# RSL15 register map
Vendor: ONSemiconductor; Series: RSL15 Series; File version: 1.0
CPU: CM33 r0p4, little endian, MPU, FPU, 3 interrupt priority bits
Registers are 32-bit, read-write, reset 0x0 unless marked. A register's access mark holds for its fields unless they carry their own. Offsets are from the block's base; [hi:lo] are bit positions; {n}, {i} and the like mark numbered series.

## NVIC — Nested Vector Interrupt Controller
Base 0xE000E100
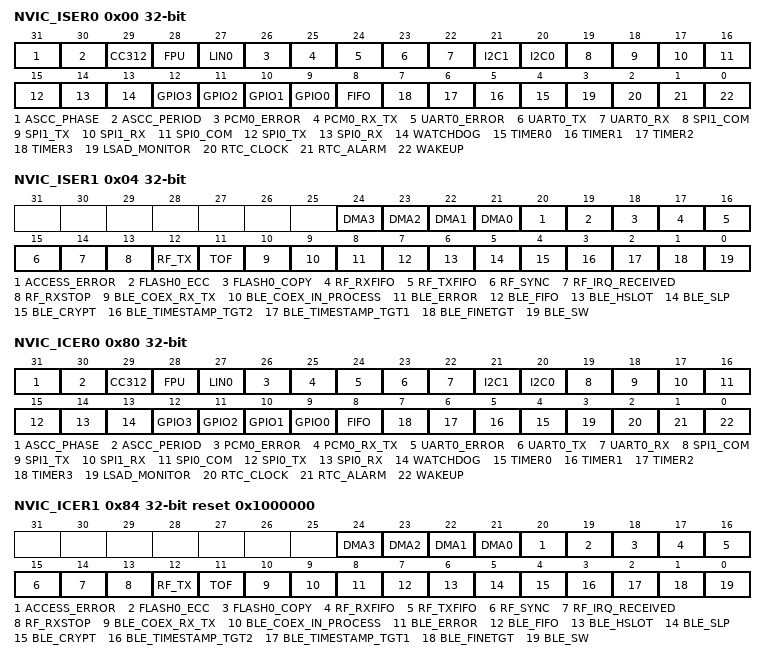
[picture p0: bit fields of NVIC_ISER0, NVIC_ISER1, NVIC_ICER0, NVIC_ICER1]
0x00 NVIC_ISER0 — NVIC External Interrupt Set Enable Register 0
  [31] ASCC_PHASE — ASCC_PHASE interrupt set enable
    1=NVIC_ASCC_PHASE_INT_ENABLE (Enable the ASCC_PHASE interrupt)
  [30] ASCC_PERIOD — ASCC_PERIOD interrupt set enable
    1=NVIC_ASCC_PERIOD_INT_ENABLE (Enable the ASCC_PERIOD interrupt)
  [29] CC312 — CC312 interrupt set enable
    1=NVIC_CC312_INT_ENABLE (Enable the CC312 interrupt)
  [28] FPU — FPU interrupt set enable
    1=NVIC_FPU_INT_ENABLE (Enable the FPU interrupt)
  [27] LIN0 — LIN0 interrupt set enable
    1=NVIC_LIN0_INT_ENABLE (Enable the LIN0 interrupt)
  [26] PCM0_ERROR — PCM0_ERROR interrupt set enable
    1=NVIC_PCM0_ERROR_INT_ENABLE (Enable the PCM0_ERROR interrupt)
  [25] PCM0_RX_TX — PCM0_RX_TX interrupt set enable
    1=NVIC_PCM0_RX_TX_INT_ENABLE (Enable the PCM0_RX_TX interrupt)
  [24] UART0_ERROR — UART0_ERROR interrupt set enable
    1=NVIC_UART0_ERROR_INT_ENABLE (Enable the UART0_ERROR interrupt)
  [23] UART0_TX — UART0_TX interrupt set enable
    1=NVIC_UART0_TX_INT_ENABLE (Enable the UART0_TX interrupt)
  [22] UART0_RX — UART0_RX interrupt set enable
    1=NVIC_UART0_RX_INT_ENABLE (Enable the UART0_RX interrupt)
  [21] I2C1 — I2C1 interrupt set enable
    1=NVIC_I2C1_INT_ENABLE (Enable the I2C1 interrupt)
  [20] I2C0 — I2C0 interrupt set enable
    1=NVIC_I2C0_INT_ENABLE (Enable the I2C0 interrupt)
  [19] SPI1_COM — SPI1_COM interrupt set enable
    1=NVIC_SPI1_COM_INT_ENABLE (Enable the SPI1_COM interrupt)
  [18] SPI1_TX — SPI1_TX interrupt set enable
    1=NVIC_SPI1_TX_INT_ENABLE (Enable the SPI1_TX interrupt)
  [17] SPI1_RX — SPI1_RX interrupt set enable
    1=NVIC_SPI1_RX_INT_ENABLE (Enable the SPI1_RX interrupt)
  [16] SPI0_COM — SPI0_COM interrupt set enable
    1=NVIC_SPI0_COM_INT_ENABLE (Enable the SPI0_COM interrupt)
  [15] SPI0_TX — SPI0_TX interrupt set enable
    1=NVIC_SPI0_TX_INT_ENABLE (Enable the SPI0_TX interrupt)
  [14] SPI0_RX — SPI0_RX interrupt set enable
    1=NVIC_SPI0_RX_INT_ENABLE (Enable the SPI0_RX interrupt)
  [13] WATCHDOG — WATCHDOG interrupt set enable
    1=NVIC_WATCHDOG_INT_ENABLE (Enable the WATCHDOG interrupt)
  [n+9] GPIO{n} (n=0..3) — GPIO{n} interrupt set enable
    1=NVIC_GPIO{n}_INT_ENABLE (Enable the GPIO{n} interrupt)
  [8] FIFO — FIFO interrupt set enable
    1=NVIC_FIFO_INT_ENABLE (Enable the FIFO interrupt)
  [n+4] TIMER{n} (n=0..3) — TIMER{n} interrupt set enable
    1=NVIC_TIMER{n}_INT_ENABLE (Enable the TIMER{n} interrupt)
  [3] LSAD_MONITOR — LSAD_MONITOR interrupt set enable
    1=NVIC_LSAD_MONITOR_INT_ENABLE (Enable the LSAD_MONITOR interrupt)
  [2] RTC_CLOCK — RTC_CLOCK interrupt set enable
    1=NVIC_RTC_CLOCK_INT_ENABLE (Enable the RTC_CLOCK interrupt)
  [1] RTC_ALARM — RTC_ALARM interrupt set enable
    1=NVIC_RTC_ALARM_INT_ENABLE (Enable the RTC_ALARM interrupt)
  [0] WAKEUP — WAKEUP interrupt set enable
    1=NVIC_WAKEUP_INT_ENABLE (Enable the WAKEUP interrupt)
0x04 NVIC_ISER1 — NVIC External Interrupt Set Enable Register 1
  [n+21] DMA{n} (n=0..3) — DMA{n} interrupt set enable
    1=NVIC_DMA{n}_INT_ENABLE (Enable the DMA{n} interrupt)
  [20] ACCESS_ERROR — ACCESS_ERROR interrupt set enable
    1=NVIC_ACCESS_ERROR_INT_ENABLE (Enable the ACCESS_ERROR interrupt)
  [19] FLASH0_ECC — FLASH0_ECC interrupt set enable
    1=NVIC_FLASH0_ECC_INT_ENABLE (Enable the FLASH0_ECC interrupt)
  [18] FLASH0_COPY — FLASH0_COPY interrupt set enable
    1=NVIC_FLASH0_COPY_INT_ENABLE (Enable the FLASH0_COPY interrupt)
  [17] RF_RXFIFO — RF_RXFIFO interrupt set enable
    1=NVIC_RF_RXFIFO_INT_ENABLE (Enable the RF_RXFIFO interrupt)
  [16] RF_TXFIFO — RF_TXFIFO interrupt set enable
    1=NVIC_RF_TXFIFO_INT_ENABLE (Enable the RF_TXFIFO interrupt)
  [15] RF_SYNC — RF_SYNC interrupt set enable
    1=NVIC_RF_SYNC_INT_ENABLE (Enable the RF_SYNC interrupt)
  [14] RF_IRQ_RECEIVED — RF_IRQ_RECEIVED interrupt set enable
    1=NVIC_RF_IRQ_RECEIVED_INT_ENABLE (Enable the RF_IRQ_RECEIVED interrupt)
  [13] RF_RXSTOP — RF_RXSTOP interrupt set enable
    1=NVIC_RF_RXSTOP_INT_ENABLE (Enable the RF_RXSTOP interrupt)
  [12] RF_TX — RF_TX interrupt set enable
    1=NVIC_RF_TX_INT_ENABLE (Enable the RF_TX interrupt)
  [11] TOF — TOF interrupt set enable
    1=NVIC_TOF_INT_ENABLE (Enable the TOF interrupt)
  [10] BLE_COEX_RX_TX — BLE_COEX_RX_TX interrupt set enable
    1=NVIC_BLE_COEX_RX_TX_INT_ENABLE (Enable the BLE_COEX_RX_TX interrupt)
  [9] BLE_COEX_IN_PROCESS — BLE_COEX_IN_PROCESS interrupt set enable
    1=NVIC_BLE_COEX_IN_PROCESS_INT_ENABLE (Enable the BLE_COEX_IN_PROCESS interrupt)
  [8] BLE_ERROR — BLE_ERROR interrupt set enable
    1=NVIC_BLE_ERROR_INT_ENABLE (Enable the BLE_ERROR interrupt)
  [7] BLE_FIFO — BLE_FIFO interrupt set enable
    1=NVIC_BLE_FIFO_INT_ENABLE (Enable the BLE_FIFO interrupt)
  [6] BLE_HSLOT — BLE_HSLOT interrupt set enable
    1=NVIC_BLE_HSLOT_INT_ENABLE (Enable the BLE_HSLOT interrupt)
  [5] BLE_SLP — BLE_SLP interrupt set enable
    1=NVIC_BLE_SLP_INT_ENABLE (Enable the BLE_SLP interrupt)
  [4] BLE_CRYPT — BLE_CRYPT interrupt set enable
    1=NVIC_BLE_CRYPT_INT_ENABLE (Enable the BLE_CRYPT interrupt)
  [3] BLE_TIMESTAMP_TGT2 — BLE_TIMESTAMP_TGT2 interrupt set enable
    1=NVIC_BLE_TIMESTAMP_TGT2_INT_ENABLE (Enable the BLE_TIMESTAMP_TGT2 interrupt)
  [2] BLE_TIMESTAMP_TGT1 — BLE_TIMESTAMP_TGT1 interrupt set enable
    1=NVIC_BLE_TIMESTAMP_TGT1_INT_ENABLE (Enable the BLE_TIMESTAMP_TGT1 interrupt)
  [1] BLE_FINETGT — BLE_FINETGT interrupt set enable
    1=NVIC_BLE_FINETGT_INT_ENABLE (Enable the BLE_FINETGT interrupt)
  [0] BLE_SW — BLE_SW interrupt set enable
    1=NVIC_BLE_SW_INT_ENABLE (Enable the BLE_SW interrupt)
0x80 NVIC_ICER0 — NVIC External Interrupt Clear Enable Register 0
  [31] ASCC_PHASE — ASCC_PHASE interrupt clear enable
    1=NVIC_ASCC_PHASE_INT_DISABLE (Disable the ASCC_PHASE interrupt)
  [30] ASCC_PERIOD — ASCC_PERIOD interrupt clear enable
    1=NVIC_ASCC_PERIOD_INT_DISABLE (Disable the ASCC_PERIOD interrupt)
  [29] CC312 — CC312 interrupt clear enable
    1=NVIC_CC312_INT_DISABLE (Disable the CC312 interrupt)
  [28] FPU — FPU interrupt clear enable
    1=NVIC_FPU_INT_DISABLE (Disable the FPU interrupt)
  [27] LIN0 — LIN0 interrupt clear enable
    1=NVIC_LIN0_INT_DISABLE (Disable the LIN0 interrupt)
  [26] PCM0_ERROR — PCM0_ERROR interrupt clear enable
    1=NVIC_PCM0_ERROR_INT_DISABLE (Disable the PCM0_ERROR interrupt)
  [25] PCM0_RX_TX — PCM0_RX_TX interrupt clear enable
    1=NVIC_PCM0_RX_TX_INT_DISABLE (Disable the PCM0_RX_TX interrupt)
  [24] UART0_ERROR — UART0_ERROR interrupt clear enable
    1=NVIC_UART0_ERROR_INT_DISABLE (Disable the UART0_ERROR interrupt)
  [23] UART0_TX — UART0_TX interrupt clear enable
    1=NVIC_UART0_TX_INT_DISABLE (Disable the UART0_TX interrupt)
  [22] UART0_RX — UART0_RX interrupt clear enable
    1=NVIC_UART0_RX_INT_DISABLE (Disable the UART0_RX interrupt)
  [21] I2C1 — I2C1 interrupt clear enable
    1=NVIC_I2C1_INT_DISABLE (Disable the I2C1 interrupt)
  [20] I2C0 — I2C0 interrupt clear enable
    1=NVIC_I2C0_INT_DISABLE (Disable the I2C0 interrupt)
  [19] SPI1_COM — SPI1_COM interrupt clear enable
    1=NVIC_SPI1_COM_INT_DISABLE (Disable the SPI1_COM interrupt)
  [18] SPI1_TX — SPI1_TX interrupt clear enable
    1=NVIC_SPI1_TX_INT_DISABLE (Disable the SPI1_TX interrupt)
  [17] SPI1_RX — SPI1_RX interrupt clear enable
    1=NVIC_SPI1_RX_INT_DISABLE (Disable the SPI1_RX interrupt)
  [16] SPI0_COM — SPI0_COM interrupt clear enable
    1=NVIC_SPI0_COM_INT_DISABLE (Disable the SPI0_COM interrupt)
  [15] SPI0_TX — SPI0_TX interrupt clear enable
    1=NVIC_SPI0_TX_INT_DISABLE (Disable the SPI0_TX interrupt)
  [14] SPI0_RX — SPI0_RX interrupt clear enable
    1=NVIC_SPI0_RX_INT_DISABLE (Disable the SPI0_RX interrupt)
  [13] WATCHDOG — WATCHDOG interrupt clear enable
    1=NVIC_WATCHDOG_INT_DISABLE (Disable the WATCHDOG interrupt)
  [n+9] GPIO{n} (n=0..3) — GPIO{n} interrupt clear enable
    1=NVIC_GPIO{n}_INT_DISABLE (Disable the GPIO{n} interrupt)
  [8] FIFO — FIFO interrupt clear enable
    1=NVIC_FIFO_INT_DISABLE (Disable the FIFO interrupt)
  [n+4] TIMER{n} (n=0..3) — TIMER{n} interrupt clear enable
    1=NVIC_TIMER{n}_INT_DISABLE (Disable the TIMER{n} interrupt)
  [3] LSAD_MONITOR — LSAD_MONITOR interrupt clear enable
    1=NVIC_LSAD_MONITOR_INT_DISABLE (Disable the LSAD_MONITOR interrupt)
  [2] RTC_CLOCK — RTC_CLOCK interrupt clear enable
    1=NVIC_RTC_CLOCK_INT_DISABLE (Disable the RTC_CLOCK interrupt)
  [1] RTC_ALARM — RTC_ALARM interrupt clear enable
    1=NVIC_RTC_ALARM_INT_DISABLE (Disable the RTC_ALARM interrupt)
  [0] WAKEUP — WAKEUP interrupt clear enable
    1=NVIC_WAKEUP_INT_DISABLE (Disable the WAKEUP interrupt)
0x84 NVIC_ICER1 reset 0x1000000 — NVIC External Interrupt Clear Enable Register 1
  [24] DMA3 — DMA3 interrupt clear enable
    0=NVIC_DMA3_INT_DISABLE (Disable the DMA3 interrupt)
  [23] DMA2 — DMA2 interrupt clear enable
    1=NVIC_DMA2_INT_DISABLE (Disable the DMA2 interrupt)
  [22] DMA1 — DMA1 interrupt clear enable
    1=NVIC_DMA1_INT_DISABLE (Disable the DMA1 interrupt)
  [21] DMA0 — DMA0 interrupt clear enable
    1=NVIC_DMA0_INT_DISABLE (Disable the DMA0 interrupt)
  [20] ACCESS_ERROR — ACCESS_ERROR interrupt clear enable
    1=NVIC_ACCESS_ERROR_INT_DISABLE (Disable the ACCESS_ERROR interrupt)
  [19] FLASH0_ECC — FLASH0_ECC interrupt clear enable
    1=NVIC_FLASH0_ECC_INT_DISABLE (Disable the FLASH0_ECC interrupt)
  [18] FLASH0_COPY — FLASH0_COPY interrupt clear enable
    1=NVIC_FLASH0_COPY_INT_DISABLE (Disable the FLASH0_COPY interrupt)
  [17] RF_RXFIFO — RF_RXFIFO interrupt clear enable
    1=NVIC_RF_RXFIFO_INT_DISABLE (Disable the RF_RXFIFO interrupt)
  [16] RF_TXFIFO — RF_TXFIFO interrupt clear enable
    1=NVIC_RF_TXFIFO_INT_DISABLE (Disable the RF_TXFIFO interrupt)
  [15] RF_SYNC — RF_SYNC interrupt clear enable
    1=NVIC_RF_SYNC_INT_DISABLE (Disable the RF_SYNC interrupt)
  [14] RF_IRQ_RECEIVED — RF_IRQ_RECEIVED interrupt clear enable
    1=NVIC_RF_IRQ_RECEIVED_INT_DISABLE (Disable the RF_IRQ_RECEIVED interrupt)
  [13] RF_RXSTOP — RF_RXSTOP interrupt clear enable
    1=NVIC_RF_RXSTOP_INT_DISABLE (Disable the RF_RXSTOP interrupt)
  [12] RF_TX — RF_TX interrupt clear enable
    1=NVIC_RF_TX_INT_DISABLE (Disable the RF_TX interrupt)
  [11] TOF — TOF interrupt clear enable
    1=NVIC_TOF_INT_DISABLE (Disable the TOF interrupt)
  [10] BLE_COEX_RX_TX — BLE_COEX_RX_TX interrupt clear enable
    1=NVIC_BLE_COEX_RX_TX_INT_DISABLE (Disable the BLE_COEX_RX_TX interrupt)
  [9] BLE_COEX_IN_PROCESS — BLE_COEX_IN_PROCESS interrupt clear enable
    1=NVIC_BLE_COEX_IN_PROCESS_INT_DISABLE (Disable the BLE_COEX_IN_PROCESS interrupt)
  [8] BLE_ERROR — BLE_ERROR interrupt clear enable
    1=NVIC_BLE_ERROR_INT_DISABLE (Disable the BLE_ERROR interrupt)
  [7] BLE_FIFO — BLE_FIFO interrupt clear enable
    1=NVIC_BLE_FIFO_INT_DISABLE (Disable the BLE_FIFO interrupt)
  [6] BLE_HSLOT — BLE_HSLOT interrupt clear enable
    1=NVIC_BLE_HSLOT_INT_DISABLE (Disable the BLE_HSLOT interrupt)
  [5] BLE_SLP — BLE_SLP interrupt clear enable
    1=NVIC_BLE_SLP_INT_DISABLE (Disable the BLE_SLP interrupt)
  [4] BLE_CRYPT — BLE_CRYPT interrupt clear enable
    1=NVIC_BLE_CRYPT_INT_DISABLE (Disable the BLE_CRYPT interrupt)
  [3] BLE_TIMESTAMP_TGT2 — BLE_TIMESTAMP_TGT2 interrupt clear enable
    1=NVIC_BLE_TIMESTAMP_TGT2_INT_DISABLE (Disable the BLE_TIMESTAMP_TGT2 interrupt)
  [2] BLE_TIMESTAMP_TGT1 — BLE_TIMESTAMP_TGT1 interrupt clear enable
    1=NVIC_BLE_TIMESTAMP_TGT1_INT_DISABLE (Disable the BLE_TIMESTAMP_TGT1 interrupt)
  [1] BLE_FINETGT — BLE_FINETGT interrupt clear enable
    1=NVIC_BLE_FINETGT_INT_DISABLE (Disable the BLE_FINETGT interrupt)
  [0] BLE_SW — BLE_SW interrupt clear enable
    1=NVIC_BLE_SW_INT_DISABLE (Disable the BLE_SW interrupt)
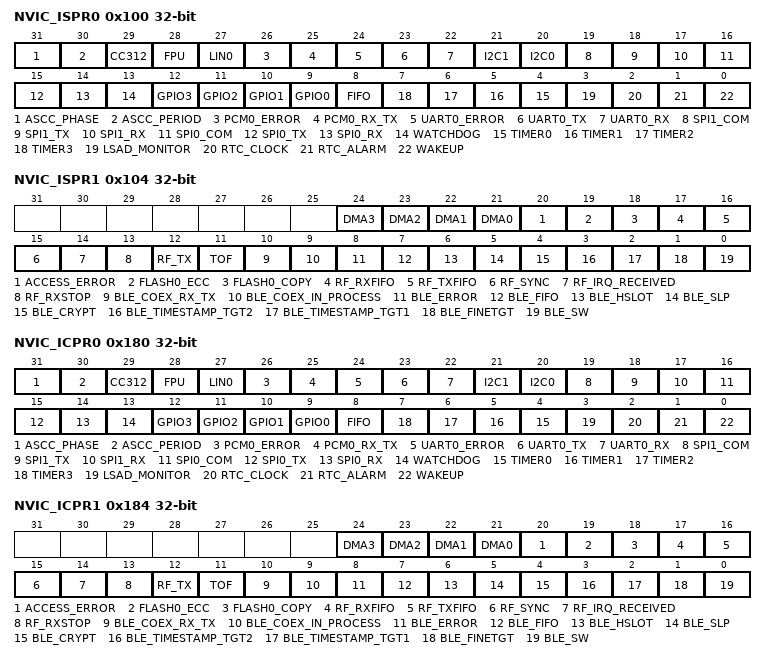
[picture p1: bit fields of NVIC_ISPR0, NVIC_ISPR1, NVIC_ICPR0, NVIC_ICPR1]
0x100 NVIC_ISPR0 — NVIC External Interrupt Set Pending Register 0
  [31] ASCC_PHASE — ASCC_PHASE interrupt set pending
    1=NVIC_ASCC_PHASE_INT_SETPEND (Set the ASCC_PHASE interrupt pending)
  [30] ASCC_PERIOD — ASCC_PERIOD interrupt set pending
    1=NVIC_ASCC_PERIOD_INT_SETPEND (Set the ASCC_PERIOD interrupt pending)
  [29] CC312 — CC312 interrupt set pending
    1=NVIC_CC312_INT_SETPEND (Set the CC312 interrupt pending)
  [28] FPU — FPU interrupt set pending
    1=NVIC_FPU_INT_SETPEND (Set the FPU interrupt pending)
  [27] LIN0 — LIN0 interrupt set pending
    1=NVIC_LIN0_INT_SETPEND (Set the LIN0 interrupt pending)
  [26] PCM0_ERROR — PCM0_ERROR interrupt set pending
    1=NVIC_PCM0_ERROR_INT_SETPEND (Set the PCM0_ERROR interrupt pending)
  [25] PCM0_RX_TX — PCM0_RX_TX interrupt set pending
    1=NVIC_PCM0_RX_TX_INT_SETPEND (Set the PCM0_RX_TX interrupt pending)
  [24] UART0_ERROR — UART0_ERROR interrupt set pending
    1=NVIC_UART0_ERROR_INT_SETPEND (Set the UART0_ERROR interrupt pending)
  [23] UART0_TX — UART0_TX interrupt set pending
    1=NVIC_UART0_TX_INT_SETPEND (Set the UART0_TX interrupt pending)
  [22] UART0_RX — UART0_RX interrupt set pending
    1=NVIC_UART0_RX_INT_SETPEND (Set the UART0_RX interrupt pending)
  [21] I2C1 — I2C1 interrupt set pending
    1=NVIC_I2C1_INT_SETPEND (Set the I2C1 interrupt pending)
  [20] I2C0 — I2C0 interrupt set pending
    1=NVIC_I2C0_INT_SETPEND (Set the I2C0 interrupt pending)
  [19] SPI1_COM — SPI1_COM interrupt set pending
    1=NVIC_SPI1_COM_INT_SETPEND (Set the SPI1_COM interrupt pending)
  [18] SPI1_TX — SPI1_TX interrupt set pending
    1=NVIC_SPI1_TX_INT_SETPEND (Set the SPI1_TX interrupt pending)
  [17] SPI1_RX — SPI1_RX interrupt set pending
    1=NVIC_SPI1_RX_INT_SETPEND (Set the SPI1_RX interrupt pending)
  [16] SPI0_COM — SPI0_COM interrupt set pending
    1=NVIC_SPI0_COM_INT_SETPEND (Set the SPI0_COM interrupt pending)
  [15] SPI0_TX — SPI0_TX interrupt set pending
    1=NVIC_SPI0_TX_INT_SETPEND (Set the SPI0_TX interrupt pending)
  [14] SPI0_RX — SPI0_RX interrupt set pending
    1=NVIC_SPI0_RX_INT_SETPEND (Set the SPI0_RX interrupt pending)
  [13] WATCHDOG — WATCHDOG interrupt set pending
    1=NVIC_WATCHDOG_INT_SETPEND (Set the WATCHDOG interrupt pending)
  [n+9] GPIO{n} (n=0..3) — GPIO{n} interrupt set pending
    1=NVIC_GPIO{n}_INT_SETPEND (Set the GPIO{n} interrupt pending)
  [8] FIFO — FIFO interrupt set pending
    1=NVIC_FIFO_INT_SETPEND (Set the FIFO interrupt pending)
  [n+4] TIMER{n} (n=0..3) — TIMER{n} interrupt set pending
    1=NVIC_TIMER{n}_INT_SETPEND (Set the TIMER{n} interrupt pending)
  [3] LSAD_MONITOR — LSAD_MONITOR interrupt set pending
    1=NVIC_LSAD_MONITOR_INT_SETPEND (Set the LSAD_MONITOR interrupt pending)
  [2] RTC_CLOCK — RTC_CLOCK interrupt set pending
    1=NVIC_RTC_CLOCK_INT_SETPEND (Set the RTC_CLOCK interrupt pending)
  [1] RTC_ALARM — RTC_ALARM interrupt set pending
    1=NVIC_RTC_ALARM_INT_SETPEND (Set the RTC_ALARM interrupt pending)
  [0] WAKEUP — WAKEUP interrupt set pending
    1=NVIC_WAKEUP_INT_SETPEND (Set the WAKEUP interrupt pending)
0x104 NVIC_ISPR1 — NVIC External Interrupt Set Pending Register 1
  [n+21] DMA{n} (n=0..3) — DMA{n} interrupt set pending
    1=NVIC_DMA{n}_INT_SETPEND (Set the DMA{n} interrupt pending)
  [20] ACCESS_ERROR — ACCESS_ERROR interrupt set pending
    1=NVIC_ACCESS_ERROR_INT_SETPEND (Set the ACCESS_ERROR interrupt pending)
  [19] FLASH0_ECC — FLASH0_ECC interrupt set pending
    1=NVIC_FLASH0_ECC_INT_SETPEND (Set the FLASH0_ECC interrupt pending)
  [18] FLASH0_COPY — FLASH0_COPY interrupt set pending
    1=NVIC_FLASH0_COPY_INT_SETPEND (Set the FLASH0_COPY interrupt pending)
  [17] RF_RXFIFO — RF_RXFIFO interrupt set pending
    1=NVIC_RF_RXFIFO_INT_SETPEND (Set the RF_RXFIFO interrupt pending)
  [16] RF_TXFIFO — RF_TXFIFO interrupt set pending
    1=NVIC_RF_TXFIFO_INT_SETPEND (Set the RF_TXFIFO interrupt pending)
  [15] RF_SYNC — RF_SYNC interrupt set pending
    1=NVIC_RF_SYNC_INT_SETPEND (Set the RF_SYNC interrupt pending)
  [14] RF_IRQ_RECEIVED — RF_IRQ_RECEIVED interrupt set pending
    1=NVIC_RF_IRQ_RECEIVED_INT_SETPEND (Set the RF_IRQ_RECEIVED interrupt pending)
  [13] RF_RXSTOP — RF_RXSTOP interrupt set pending
    1=NVIC_RF_RXSTOP_INT_SETPEND (Set the RF_RXSTOP interrupt pending)
  [12] RF_TX — RF_TX interrupt set pending
    1=NVIC_RF_TX_INT_SETPEND (Set the RF_TX interrupt pending)
  [11] TOF — TOF interrupt set pending
    1=NVIC_TOF_INT_SETPEND (Set the TOF interrupt pending)
  [10] BLE_COEX_RX_TX — BLE_COEX_RX_TX interrupt set pending
    1=NVIC_BLE_COEX_RX_TX_INT_SETPEND (Set the BLE_COEX_RX_TX interrupt pending)
  [9] BLE_COEX_IN_PROCESS — BLE_COEX_IN_PROCESS interrupt set pending
    1=NVIC_BLE_COEX_IN_PROCESS_INT_SETPEND (Set the BLE_COEX_IN_PROCESS interrupt pending)
  [8] BLE_ERROR — BLE_ERROR interrupt set pending
    1=NVIC_BLE_ERROR_INT_SETPEND (Set the BLE_ERROR interrupt pending)
  [7] BLE_FIFO — BLE_FIFO interrupt set pending
    1=NVIC_BLE_FIFO_INT_SETPEND (Set the BLE_FIFO interrupt pending)
  [6] BLE_HSLOT — BLE_HSLOT interrupt set pending
    1=NVIC_BLE_HSLOT_INT_SETPEND (Set the BLE_HSLOT interrupt pending)
  [5] BLE_SLP — BLE_SLP interrupt set pending
    1=NVIC_BLE_SLP_INT_SETPEND (Set the BLE_SLP interrupt pending)
  [4] BLE_CRYPT — BLE_CRYPT interrupt set pending
    1=NVIC_BLE_CRYPT_INT_SETPEND (Set the BLE_CRYPT interrupt pending)
  [3] BLE_TIMESTAMP_TGT2 — BLE_TIMESTAMP_TGT2 interrupt set pending
    1=NVIC_BLE_TIMESTAMP_TGT2_INT_SETPEND (Set the BLE_TIMESTAMP_TGT2 interrupt pending)
  [2] BLE_TIMESTAMP_TGT1 — BLE_TIMESTAMP_TGT1 interrupt set pending
    1=NVIC_BLE_TIMESTAMP_TGT1_INT_SETPEND (Set the BLE_TIMESTAMP_TGT1 interrupt pending)
  [1] BLE_FINETGT — BLE_FINETGT interrupt set pending
    1=NVIC_BLE_FINETGT_INT_SETPEND (Set the BLE_FINETGT interrupt pending)
  [0] BLE_SW — BLE_SW interrupt set pending
    1=NVIC_BLE_SW_INT_SETPEND (Set the BLE_SW interrupt pending)
0x180 NVIC_ICPR0 — NVIC External Interrupt Clear Pending Register 0
  [31] ASCC_PHASE — ASCC_PHASE interrupt clear pending
    1=NVIC_ASCC_PHASE_INT_CLRPEND (Clear the NVIC_ASCC_PHASE_INT_CLRPEND interrupt status bit)
  [30] ASCC_PERIOD — ASCC_PERIOD interrupt clear pending
    1=NVIC_ASCC_PERIOD_INT_CLRPEND (Clear the NVIC_ASCC_PERIOD_INT_CLRPEND interrupt status bit)
  [29] CC312 — CC312 interrupt clear pending
    1=NVIC_CC312_INT_CLRPEND (Clear the NVIC_CC312_INT_CLRPEND interrupt status bit)
  [28] FPU — FPU interrupt clear pending
    1=NVIC_FPU_INT_CLRPEND (Clear the NVIC_FPU_INT_CLRPEND interrupt status bit)
  [27] LIN0 — LIN0 interrupt clear pending
    1=NVIC_LIN0_INT_CLRPEND (Clear the NVIC_LIN0_INT_CLRPEND interrupt status bit)
  [26] PCM0_ERROR — PCM0_ERROR interrupt clear pending
    1=NVIC_PCM0_ERROR_INT_CLRPEND (Clear the NVIC_PCM0_ERROR_INT_CLRPEND interrupt status bit)
  [25] PCM0_RX_TX — PCM0_RX_TX interrupt clear pending
    1=NVIC_PCM0_RX_TX_INT_CLRPEND (Clear the NVIC_PCM0_RX_TX_INT_CLRPEND interrupt status bit)
  [24] UART0_ERROR — UART0_ERROR interrupt clear pending
    1=NVIC_UART0_ERROR_INT_CLRPEND (Clear the NVIC_UART0_ERROR_INT_CLRPEND interrupt status bit)
  [23] UART0_TX — UART0_TX interrupt clear pending
    1=NVIC_UART0_TX_INT_CLRPEND (Clear the NVIC_UART0_TX_INT_CLRPEND interrupt status bit)
  [22] UART0_RX — UART0_RX interrupt clear pending
    1=NVIC_UART0_RX_INT_CLRPEND (Clear the NVIC_UART0_RX_INT_CLRPEND interrupt status bit)
  [21] I2C1 — I2C1 interrupt clear pending
    1=NVIC_I2C1_INT_CLRPEND (Clear the NVIC_I2C1_INT_CLRPEND interrupt status bit)
  [20] I2C0 — I2C0 interrupt clear pending
    1=NVIC_I2C0_INT_CLRPEND (Clear the NVIC_I2C0_INT_CLRPEND interrupt status bit)
  [19] SPI1_COM — SPI1_COM interrupt clear pending
    1=NVIC_SPI1_COM_INT_CLRPEND (Clear the NVIC_SPI1_COM_INT_CLRPEND interrupt status bit)
  [18] SPI1_TX — SPI1_TX interrupt clear pending
    1=NVIC_SPI1_TX_INT_CLRPEND (Clear the NVIC_SPI1_TX_INT_CLRPEND interrupt status bit)
  [17] SPI1_RX — SPI1_RX interrupt clear pending
    1=NVIC_SPI1_RX_INT_CLRPEND (Clear the NVIC_SPI1_RX_INT_CLRPEND interrupt status bit)
  [16] SPI0_COM — SPI0_COM interrupt clear pending
    1=NVIC_SPI0_COM_INT_CLRPEND (Clear the NVIC_SPI0_COM_INT_CLRPEND interrupt status bit)
  [15] SPI0_TX — SPI0_TX interrupt clear pending
    1=NVIC_SPI0_TX_INT_CLRPEND (Clear the NVIC_SPI0_TX_INT_CLRPEND interrupt status bit)
  [14] SPI0_RX — SPI0_RX interrupt clear pending
    1=NVIC_SPI0_RX_INT_CLRPEND (Clear the NVIC_SPI0_RX_INT_CLRPEND interrupt status bit)
  [13] WATCHDOG — WATCHDOG interrupt clear pending
    1=NVIC_WATCHDOG_INT_CLRPEND (Clear the NVIC_WATCHDOG_INT_CLRPEND interrupt status bit)
  [n+9] GPIO{n} (n=0..3) — GPIO{n} interrupt clear pending
    1=NVIC_GPIO{n}_INT_CLRPEND (Clear the NVIC_GPIO{n}_INT_CLRPEND interrupt status bit)
  [8] FIFO — FIFO interrupt clear pending
    1=NVIC_FIFO_INT_CLRPEND (Clear the NVIC_FIFO_INT_CLRPEND interrupt status bit)
  [n+4] TIMER{n} (n=0..3) — TIMER{n} interrupt clear pending
    1=NVIC_TIMER{n}_INT_CLRPEND (Clear the NVIC_TIMER{n}_INT_CLRPEND interrupt status bit)
  [3] LSAD_MONITOR — LSAD_MONITOR interrupt clear pending
    1=NVIC_LSAD_MONITOR_INT_CLRPEND (Clear the NVIC_LSAD_MONITOR_INT_CLRPEND interrupt status bit)
  [2] RTC_CLOCK — RTC_CLOCK interrupt clear pending
    1=NVIC_RTC_CLOCK_INT_CLRPEND (Clear the NVIC_RTC_CLOCK_INT_CLRPEND interrupt status bit)
  [1] RTC_ALARM — RTC_ALARM interrupt clear pending
    1=NVIC_RTC_ALARM_INT_CLRPEND (Clear the NVIC_RTC_ALARM_INT_CLRPEND interrupt status bit)
  [0] WAKEUP — WAKEUP interrupt clear pending
    1=NVIC_WAKEUP_INT_CLRPEND (Clear the NVIC_WAKEUP_INT_CLRPEND interrupt status bit)
0x184 NVIC_ICPR1 — NVIC External Interrupt Clear Pending Register 1
  [n+21] DMA{n} (n=0..3) — DMA{n} interrupt clear pending
    1=NVIC_DMA{n}_INT_CLRPEND (Clear the NVIC_DMA{n}_INT_CLRPEND interrupt status bit)
  [20] ACCESS_ERROR — ACCESS_ERROR interrupt clear pending
    1=NVIC_ACCESS_ERROR_INT_CLRPEND (Clear the NVIC_ACCESS_ERROR_INT_CLRPEND interrupt status bit)
  [19] FLASH0_ECC — FLASH0_ECC interrupt clear pending
    1=NVIC_FLASH0_ECC_INT_CLRPEND (Clear the NVIC_FLASH0_ECC_INT_CLRPEND interrupt status bit)
  [18] FLASH0_COPY — FLASH0_COPY interrupt clear pending
    1=NVIC_FLASH0_COPY_INT_CLRPEND (Clear the NVIC_FLASH0_COPY_INT_CLRPEND interrupt status bit)
  [17] RF_RXFIFO — RF_RXFIFO interrupt clear pending
    1=NVIC_RF_RXFIFO_INT_CLRPEND (Clear the NVIC_RF_RXFIFO_INT_CLRPEND interrupt status bit)
  [16] RF_TXFIFO — RF_TXFIFO interrupt clear pending
    1=NVIC_RF_TXFIFO_INT_CLRPEND (Clear the NVIC_RF_TXFIFO_INT_CLRPEND interrupt status bit)
  [15] RF_SYNC — RF_SYNC interrupt clear pending
    1=NVIC_RF_SYNC_INT_CLRPEND (Clear the NVIC_RF_SYNC_INT_CLRPEND interrupt status bit)
  [14] RF_IRQ_RECEIVED — RF_IRQ_RECEIVED interrupt clear pending
    1=NVIC_RF_IRQ_RECEIVED_INT_CLRPEND (Clear the NVIC_RF_IRQ_RECEIVED_INT_CLRPEND interrupt status bit)
  [13] RF_RXSTOP — RF_RXSTOP interrupt clear pending
    1=NVIC_RF_RXSTOP_INT_CLRPEND (Clear the NVIC_RF_RXSTOP_INT_CLRPEND interrupt status bit)
  [12] RF_TX — RF_TX interrupt clear pending
    1=NVIC_RF_TX_INT_CLRPEND (Clear the NVIC_RF_TX_INT_CLRPEND interrupt status bit)
  [11] TOF — TOF interrupt clear pending
    1=NVIC_TOF_INT_CLRPEND (Clear the NVIC_TOF_INT_CLRPEND interrupt status bit)
  [10] BLE_COEX_RX_TX — BLE_COEX_RX_TX interrupt clear pending
    1=NVIC_BLE_COEX_RX_TX_INT_CLRPEND (Clear the NVIC_BLE_COEX_RX_TX_INT_CLRPEND interrupt status bit)
  [9] BLE_COEX_IN_PROCESS — BLE_COEX_IN_PROCESS interrupt clear pending
    1=NVIC_BLE_COEX_IN_PROCESS_INT_CLRPEND (Clear the NVIC_BLE_COEX_IN_PROCESS_INT_CLRPEND interrupt status bit)
  [8] BLE_ERROR — BLE_ERROR interrupt clear pending
    1=NVIC_BLE_ERROR_INT_CLRPEND (Clear the NVIC_BLE_ERROR_INT_CLRPEND interrupt status bit)
  [7] BLE_FIFO — BLE_FIFO interrupt clear pending
    1=NVIC_BLE_FIFO_INT_CLRPEND (Clear the NVIC_BLE_FIFO_INT_CLRPEND interrupt status bit)
  [6] BLE_HSLOT — BLE_HSLOT interrupt clear pending
    1=NVIC_BLE_HSLOT_INT_CLRPEND (Clear the NVIC_BLE_HSLOT_INT_CLRPEND interrupt status bit)
  [5] BLE_SLP — BLE_SLP interrupt clear pending
    1=NVIC_BLE_SLP_INT_CLRPEND (Clear the NVIC_BLE_SLP_INT_CLRPEND interrupt status bit)
  [4] BLE_CRYPT — BLE_CRYPT interrupt clear pending
    1=NVIC_BLE_CRYPT_INT_CLRPEND (Clear the NVIC_BLE_CRYPT_INT_CLRPEND interrupt status bit)
  [3] BLE_TIMESTAMP_TGT2 — BLE_TIMESTAMP_TGT2 interrupt clear pending
    1=NVIC_BLE_TIMESTAMP_TGT2_INT_CLRPEND (Clear the NVIC_BLE_TIMESTAMP_TGT2_INT_CLRPEND interrupt status bit)
  [2] BLE_TIMESTAMP_TGT1 — BLE_TIMESTAMP_TGT1 interrupt clear pending
    1=NVIC_BLE_TIMESTAMP_TGT1_INT_CLRPEND (Clear the NVIC_BLE_TIMESTAMP_TGT1_INT_CLRPEND interrupt status bit)
  [1] BLE_FINETGT — BLE_FINETGT interrupt clear pending
    1=NVIC_BLE_FINETGT_INT_CLRPEND (Clear the NVIC_BLE_FINETGT_INT_CLRPEND interrupt status bit)
  [0] BLE_SW — BLE_SW interrupt clear pending
    1=NVIC_BLE_SW_INT_CLRPEND (Clear the NVIC_BLE_SW_INT_CLRPEND interrupt status bit)
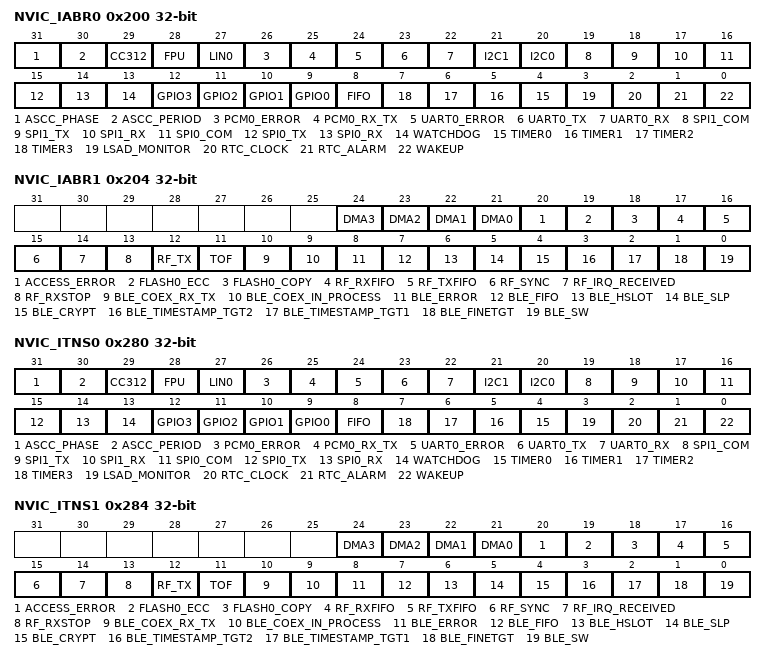
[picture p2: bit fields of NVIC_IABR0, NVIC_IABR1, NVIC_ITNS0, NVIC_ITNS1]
0x200 NVIC_IABR0 ro — NVIC External Interrupt Active Register 0
  [31] ASCC_PHASE — Set the ASCC_PHASE interrupt as active
    1=NVIC_ASCC_PHASE_INT_ACTIVE (The NVIC_ASCC_PHASE_INT_ACTIVE interrupt is active)
  [30] ASCC_PERIOD — Set the ASCC_PERIOD interrupt as active
    1=NVIC_ASCC_PERIOD_INT_ACTIVE (The NVIC_ASCC_PERIOD_INT_ACTIVE interrupt is active)
  [29] CC312 — Set the CC312 interrupt as active
    1=NVIC_CC312_INT_ACTIVE (The NVIC_CC312_INT_ACTIVE interrupt is active)
  [28] FPU — Set the FPU interrupt as active
    1=NVIC_FPU_INT_ACTIVE (The NVIC_FPU_INT_ACTIVE interrupt is active)
  [27] LIN0 — Set the LIN0 interrupt as active
    1=NVIC_LIN0_INT_ACTIVE (The NVIC_LIN0_INT_ACTIVE interrupt is active)
  [26] PCM0_ERROR — Set the PCM0_ERROR interrupt as active
    1=NVIC_PCM0_ERROR_INT_ACTIVE (The NVIC_PCM0_ERROR_INT_ACTIVE interrupt is active)
  [25] PCM0_RX_TX — Set the PCM0_RX_TX interrupt as active
    1=NVIC_PCM0_RX_TX_INT_ACTIVE (The NVIC_PCM0_RX_TX_INT_ACTIVE interrupt is active)
  [24] UART0_ERROR — Set the UART0_ERROR interrupt as active
    1=NVIC_UART0_ERROR_INT_ACTIVE (The NVIC_UART0_ERROR_INT_ACTIVE interrupt is active)
  [23] UART0_TX — Set the UART0_TX interrupt as active
    1=NVIC_UART0_TX_INT_ACTIVE (The NVIC_UART0_TX_INT_ACTIVE interrupt is active)
  [22] UART0_RX — Set the UART0_RX interrupt as active
    1=NVIC_UART0_RX_INT_ACTIVE (The NVIC_UART0_RX_INT_ACTIVE interrupt is active)
  [21] I2C1 — Set the I2C1 interrupt as active
    1=NVIC_I2C1_INT_ACTIVE (The NVIC_I2C1_INT_ACTIVE interrupt is active)
  [20] I2C0 — Set the I2C0 interrupt as active
    1=NVIC_I2C0_INT_ACTIVE (The NVIC_I2C0_INT_ACTIVE interrupt is active)
  [19] SPI1_COM — Set the SPI1_COM interrupt as active
    1=NVIC_SPI1_COM_INT_ACTIVE (The NVIC_SPI1_COM_INT_ACTIVE interrupt is active)
  [18] SPI1_TX — Set the SPI1_TX interrupt as active
    1=NVIC_SPI1_TX_INT_ACTIVE (The NVIC_SPI1_TX_INT_ACTIVE interrupt is active)
  [17] SPI1_RX — Set the SPI1_RX interrupt as active
    1=NVIC_SPI1_RX_INT_ACTIVE (The NVIC_SPI1_RX_INT_ACTIVE interrupt is active)
  [16] SPI0_COM — Set the SPI0_COM interrupt as active
    1=NVIC_SPI0_COM_INT_ACTIVE (The NVIC_SPI0_COM_INT_ACTIVE interrupt is active)
  [15] SPI0_TX — Set the SPI0_TX interrupt as active
    1=NVIC_SPI0_TX_INT_ACTIVE (The NVIC_SPI0_TX_INT_ACTIVE interrupt is active)
  [14] SPI0_RX — Set the SPI0_RX interrupt as active
    1=NVIC_SPI0_RX_INT_ACTIVE (The NVIC_SPI0_RX_INT_ACTIVE interrupt is active)
  [13] WATCHDOG — Set the WATCHDOG interrupt as active
    1=NVIC_WATCHDOG_INT_ACTIVE (The NVIC_WATCHDOG_INT_ACTIVE interrupt is active)
  [n+9] GPIO{n} (n=0..3) — Set the GPIO{n} interrupt as active
    1=NVIC_GPIO{n}_INT_ACTIVE (The NVIC_GPIO{n}_INT_ACTIVE interrupt is active)
  [8] FIFO — Set the FIFO interrupt as active
    1=NVIC_FIFO_INT_ACTIVE (The NVIC_FIFO_INT_ACTIVE interrupt is active)
  [n+4] TIMER{n} (n=0..3) — Set the TIMER{n} interrupt as active
    1=NVIC_TIMER{n}_INT_ACTIVE (The NVIC_TIMER{n}_INT_ACTIVE interrupt is active)
  [3] LSAD_MONITOR — Set the LSAD_MONITOR interrupt as active
    1=NVIC_LSAD_MONITOR_INT_ACTIVE (The NVIC_LSAD_MONITOR_INT_ACTIVE interrupt is active)
  [2] RTC_CLOCK — Set the RTC_CLOCK interrupt as active
    1=NVIC_RTC_CLOCK_INT_ACTIVE (The NVIC_RTC_CLOCK_INT_ACTIVE interrupt is active)
  [1] RTC_ALARM — Set the RTC_ALARM interrupt as active
    1=NVIC_RTC_ALARM_INT_ACTIVE (The NVIC_RTC_ALARM_INT_ACTIVE interrupt is active)
  [0] WAKEUP — Set the WAKEUP interrupt as active
    1=NVIC_WAKEUP_INT_ACTIVE (The NVIC_WAKEUP_INT_ACTIVE interrupt is active)
0x204 NVIC_IABR1 ro — NVIC External Interrupt Active Register 1
  [n+21] DMA{n} (n=0..3) — Set the DMA{n} interrupt as active
    1=NVIC_DMA{n}_INT_ACTIVE (The NVIC_DMA{n}_INT_ACTIVE interrupt is active)
  [20] ACCESS_ERROR — Set the ACCESS_ERROR interrupt as active
    1=NVIC_ACCESS_ERROR_INT_ACTIVE (The NVIC_ACCESS_ERROR_INT_ACTIVE interrupt is active)
  [19] FLASH0_ECC — Set the FLASH0_ECC interrupt as active
    1=NVIC_FLASH0_ECC_INT_ACTIVE (The NVIC_FLASH0_ECC_INT_ACTIVE interrupt is active)
  [18] FLASH0_COPY — Set the FLASH0_COPY interrupt as active
    1=NVIC_FLASH0_COPY_INT_ACTIVE (The NVIC_FLASH0_COPY_INT_ACTIVE interrupt is active)
  [17] RF_RXFIFO — Set the RF_RXFIFO interrupt as active
    1=NVIC_RF_RXFIFO_INT_ACTIVE (The NVIC_RF_RXFIFO_INT_ACTIVE interrupt is active)
  [16] RF_TXFIFO — Set the RF_TXFIFO interrupt as active
    1=NVIC_RF_TXFIFO_INT_ACTIVE (The NVIC_RF_TXFIFO_INT_ACTIVE interrupt is active)
  [15] RF_SYNC — Set the RF_SYNC interrupt as active
    1=NVIC_RF_SYNC_INT_ACTIVE (The NVIC_RF_SYNC_INT_ACTIVE interrupt is active)
  [14] RF_IRQ_RECEIVED — Set the RF_IRQ_RECEIVED interrupt as active
    1=NVIC_RF_IRQ_RECEIVED_INT_ACTIVE (The NVIC_RF_IRQ_RECEIVED_INT_ACTIVE interrupt is active)
  [13] RF_RXSTOP — Set the RF_RXSTOP interrupt as active
    1=NVIC_RF_RXSTOP_INT_ACTIVE (The NVIC_RF_RXSTOP_INT_ACTIVE interrupt is active)
  [12] RF_TX — Set the RF_TX interrupt as active
    1=NVIC_RF_TX_INT_ACTIVE (The NVIC_RF_TX_INT_ACTIVE interrupt is active)
  [11] TOF — Set the TOF interrupt as active
    1=NVIC_TOF_INT_ACTIVE (The NVIC_TOF_INT_ACTIVE interrupt is active)
  [10] BLE_COEX_RX_TX — Set the BLE_COEX_RX_TX interrupt as active
    1=NVIC_BLE_COEX_RX_TX_INT_ACTIVE (The NVIC_BLE_COEX_RX_TX_INT_ACTIVE interrupt is active)
  [9] BLE_COEX_IN_PROCESS — Set the BLE_COEX_IN_PROCESS interrupt as active
    1=NVIC_BLE_COEX_IN_PROCESS_INT_ACTIVE (The NVIC_BLE_COEX_IN_PROCESS_INT_ACTIVE interrupt is active)
  [8] BLE_ERROR — Set the BLE_ERROR interrupt as active
    1=NVIC_BLE_ERROR_INT_ACTIVE (The NVIC_BLE_ERROR_INT_ACTIVE interrupt is active)
  [7] BLE_FIFO — Set the BLE_FIFO interrupt as active
    1=NVIC_BLE_FIFO_INT_ACTIVE (The NVIC_BLE_FIFO_INT_ACTIVE interrupt is active)
  [6] BLE_HSLOT — Set the BLE_HSLOT interrupt as active
    1=NVIC_BLE_HSLOT_INT_ACTIVE (The NVIC_BLE_HSLOT_INT_ACTIVE interrupt is active)
  [5] BLE_SLP — Set the BLE_SLP interrupt as active
    1=NVIC_BLE_SLP_INT_ACTIVE (The NVIC_BLE_SLP_INT_ACTIVE interrupt is active)
  [4] BLE_CRYPT — Set the BLE_CRYPT interrupt as active
    1=NVIC_BLE_CRYPT_INT_ACTIVE (The NVIC_BLE_CRYPT_INT_ACTIVE interrupt is active)
  [3] BLE_TIMESTAMP_TGT2 — Set the BLE_TIMESTAMP_TGT2 interrupt as active
    1=NVIC_BLE_TIMESTAMP_TGT2_INT_ACTIVE (The NVIC_BLE_TIMESTAMP_TGT2_INT_ACTIVE interrupt is active)
  [2] BLE_TIMESTAMP_TGT1 — Set the BLE_TIMESTAMP_TGT1 interrupt as active
    1=NVIC_BLE_TIMESTAMP_TGT1_INT_ACTIVE (The NVIC_BLE_TIMESTAMP_TGT1_INT_ACTIVE interrupt is active)
  [1] BLE_FINETGT — Set the BLE_FINETGT interrupt as active
    1=NVIC_BLE_FINETGT_INT_ACTIVE (The NVIC_BLE_FINETGT_INT_ACTIVE interrupt is active)
  [0] BLE_SW — Set the BLE_SW interrupt as active
    1=NVIC_BLE_SW_INT_ACTIVE (The NVIC_BLE_SW_INT_ACTIVE interrupt is active)
0x280 NVIC_ITNS0 — NVIC External Interrupt Non-secure Register 0
  [31] ASCC_PHASE — Set the ASCC_PHASE interrupt as non-secure
    1=NVIC_ASCC_PHASE_INT_NON_SECURE (The NVIC_ASCC_PHASE_INT_NON_SECURE interrupt is non-secure)
  [30] ASCC_PERIOD — Set the ASCC_PERIOD interrupt as non-secure
    1=NVIC_ASCC_PERIOD_INT_NON_SECURE (The NVIC_ASCC_PERIOD_INT_NON_SECURE interrupt is non-secure)
  [29] CC312 — Set the CC312 interrupt as non-secure
    1=NVIC_CC312_INT_NON_SECURE (The NVIC_CC312_INT_NON_SECURE interrupt is non-secure)
  [28] FPU — Set the FPU interrupt as non-secure
    1=NVIC_FPU_INT_NON_SECURE (The NVIC_FPU_INT_NON_SECURE interrupt is non-secure)
  [27] LIN0 — Set the LIN0 interrupt as non-secure
    1=NVIC_LIN0_INT_NON_SECURE (The NVIC_LIN0_INT_NON_SECURE interrupt is non-secure)
  [26] PCM0_ERROR — Set the PCM0_ERROR interrupt as non-secure
    1=NVIC_PCM0_ERROR_INT_NON_SECURE (The NVIC_PCM0_ERROR_INT_NON_SECURE interrupt is non-secure)
  [25] PCM0_RX_TX — Set the PCM0_RX_TX interrupt as non-secure
    1=NVIC_PCM0_RX_TX_INT_NON_SECURE (The NVIC_PCM0_RX_TX_INT_NON_SECURE interrupt is non-secure)
  [24] UART0_ERROR — Set the UART0_ERROR interrupt as non-secure
    1=NVIC_UART0_ERROR_INT_NON_SECURE (The NVIC_UART0_ERROR_INT_NON_SECURE interrupt is non-secure)
  [23] UART0_TX — Set the UART0_TX interrupt as non-secure
    1=NVIC_UART0_TX_INT_NON_SECURE (The NVIC_UART0_TX_INT_NON_SECURE interrupt is non-secure)
  [22] UART0_RX — Set the UART0_RX interrupt as non-secure
    1=NVIC_UART0_RX_INT_NON_SECURE (The NVIC_UART0_RX_INT_NON_SECURE interrupt is non-secure)
  [21] I2C1 — Set the I2C1 interrupt as non-secure
    1=NVIC_I2C1_INT_NON_SECURE (The NVIC_I2C1_INT_NON_SECURE interrupt is non-secure)
  [20] I2C0 — Set the I2C0 interrupt as non-secure
    1=NVIC_I2C0_INT_NON_SECURE (The NVIC_I2C0_INT_NON_SECURE interrupt is non-secure)
  [19] SPI1_COM — Set the SPI1_COM interrupt as non-secure
    1=NVIC_SPI1_COM_INT_NON_SECURE (The NVIC_SPI1_COM_INT_NON_SECURE interrupt is non-secure)
  [18] SPI1_TX — Set the SPI1_TX interrupt as non-secure
    1=NVIC_SPI1_TX_INT_NON_SECURE (The NVIC_SPI1_TX_INT_NON_SECURE interrupt is non-secure)
  [17] SPI1_RX — Set the SPI1_RX interrupt as non-secure
    1=NVIC_SPI1_RX_INT_NON_SECURE (The NVIC_SPI1_RX_INT_NON_SECURE interrupt is non-secure)
  [16] SPI0_COM — Set the SPI0_COM interrupt as non-secure
    1=NVIC_SPI0_COM_INT_NON_SECURE (The NVIC_SPI0_COM_INT_NON_SECURE interrupt is non-secure)
  [15] SPI0_TX — Set the SPI0_TX interrupt as non-secure
    1=NVIC_SPI0_TX_INT_NON_SECURE (The NVIC_SPI0_TX_INT_NON_SECURE interrupt is non-secure)
  [14] SPI0_RX — Set the SPI0_RX interrupt as non-secure
    1=NVIC_SPI0_RX_INT_NON_SECURE (The NVIC_SPI0_RX_INT_NON_SECURE interrupt is non-secure)
  [13] WATCHDOG — Set the WATCHDOG interrupt as non-secure
    1=NVIC_WATCHDOG_INT_NON_SECURE (The NVIC_WATCHDOG_INT_NON_SECURE interrupt is non-secure)
  [n+9] GPIO{n} (n=0..3) — Set the GPIO{n} interrupt as non-secure
    1=NVIC_GPIO{n}_INT_NON_SECURE (The NVIC_GPIO{n}_INT_NON_SECURE interrupt is non-secure)
  [8] FIFO — Set the FIFO interrupt as non-secure
    1=NVIC_FIFO_INT_NON_SECURE (The NVIC_FIFO_INT_NON_SECURE interrupt is non-secure)
  [n+4] TIMER{n} (n=0..3) — Set the TIMER{n} interrupt as non-secure
    1=NVIC_TIMER{n}_INT_NON_SECURE (The NVIC_TIMER{n}_INT_NON_SECURE interrupt is non-secure)
  [3] LSAD_MONITOR — Set the LSAD_MONITOR interrupt as non-secure
    1=NVIC_LSAD_MONITOR_INT_NON_SECURE (The NVIC_LSAD_MONITOR_INT_NON_SECURE interrupt is non-secure)
  [2] RTC_CLOCK — Set the RTC_CLOCK interrupt as non-secure
    1=NVIC_RTC_CLOCK_INT_NON_SECURE (The NVIC_RTC_CLOCK_INT_NON_SECURE interrupt is non-secure)
  [1] RTC_ALARM — Set the RTC_ALARM interrupt as non-secure
    1=NVIC_RTC_ALARM_INT_NON_SECURE (The NVIC_RTC_ALARM_INT_NON_SECURE interrupt is non-secure)
  [0] WAKEUP — Set the WAKEUP interrupt as non-secure
    1=NVIC_WAKEUP_INT_NON_SECURE (The NVIC_WAKEUP_INT_NON_SECURE interrupt is non-secure)
0x284 NVIC_ITNS1 — NVIC External Interrupt Non-secure Register 1
  [n+21] DMA{n} (n=0..3) — Set the DMA{n} interrupt as non-secure
    1=NVIC_DMA{n}_INT_NON_SECURE (The NVIC_DMA{n}_INT_NON_SECURE interrupt is active)
  [20] ACCESS_ERROR — Set the ACCESS_ERROR interrupt as non-secure
    1=NVIC_ACCESS_ERROR_INT_NON_SECURE (The NVIC_ACCESS_ERROR_INT_NON_SECURE interrupt is active)
  [19] FLASH0_ECC — Set the FLASH0_ECC interrupt as non-secure
    1=NVIC_FLASH0_ECC_INT_NON_SECURE (The NVIC_FLASH0_ECC_INT_NON_SECURE interrupt is active)
  [18] FLASH0_COPY — Set the FLASH0_COPY interrupt as non-secure
    1=NVIC_FLASH0_COPY_INT_NON_SECURE (The NVIC_FLASH0_COPY_INT_NON_SECURE interrupt is active)
  [17] RF_RXFIFO — Set the RF_RXFIFO interrupt as non-secure
    1=NVIC_RF_RXFIFO_INT_NON_SECURE (The NVIC_RF_RXFIFO_INT_NON_SECURE interrupt is active)
  [16] RF_TXFIFO — Set the RF_TXFIFO interrupt as non-secure
    1=NVIC_RF_TXFIFO_INT_NON_SECURE (The NVIC_RF_TXFIFO_INT_NON_SECURE interrupt is active)
  [15] RF_SYNC — Set the RF_SYNC interrupt as non-secure
    1=NVIC_RF_SYNC_INT_NON_SECURE (The NVIC_RF_SYNC_INT_NON_SECURE interrupt is active)
  [14] RF_IRQ_RECEIVED — Set the RF_IRQ_RECEIVED interrupt as non-secure
    1=NVIC_RF_IRQ_RECEIVED_INT_NON_SECURE (The NVIC_RF_IRQ_RECEIVED_INT_NON_SECURE interrupt is active)
  [13] RF_RXSTOP — Set the RF_RXSTOP interrupt as non-secure
    1=NVIC_RF_RXSTOP_INT_NON_SECURE (The NVIC_RF_RXSTOP_INT_NON_SECURE interrupt is active)
  [12] RF_TX — Set the RF_TX interrupt as non-secure
    1=NVIC_RF_TX_INT_NON_SECURE (The NVIC_RF_TX_INT_NON_SECURE interrupt is active)
  [11] TOF — Set the TOF interrupt as non-secure
    1=NVIC_TOF_INT_NON_SECURE (The NVIC_TOF_INT_NON_SECURE interrupt is active)
  [10] BLE_COEX_RX_TX — Set the BLE_COEX_RX_TX interrupt as non-secure
    1=NVIC_BLE_COEX_RX_TX_INT_NON_SECURE (The NVIC_BLE_COEX_RX_TX_INT_NON_SECURE interrupt is active)
  [9] BLE_COEX_IN_PROCESS — Set the BLE_COEX_IN_PROCESS interrupt as non-secure
    1=NVIC_BLE_COEX_IN_PROCESS_INT_NON_SECURE (The NVIC_BLE_COEX_IN_PROCESS_INT_NON_SECURE interrupt is active)
  [8] BLE_ERROR — Set the BLE_ERROR interrupt as non-secure
    1=NVIC_BLE_ERROR_INT_NON_SECURE (The NVIC_BLE_ERROR_INT_NON_SECURE interrupt is active)
  [7] BLE_FIFO — Set the BLE_FIFO interrupt as non-secure
    1=NVIC_BLE_FIFO_INT_NON_SECURE (The NVIC_BLE_FIFO_INT_NON_SECURE interrupt is active)
  [6] BLE_HSLOT — Set the BLE_HSLOT interrupt as non-secure
    1=NVIC_BLE_HSLOT_INT_NON_SECURE (The NVIC_BLE_HSLOT_INT_NON_SECURE interrupt is active)
  [5] BLE_SLP — Set the BLE_SLP interrupt as non-secure
    1=NVIC_BLE_SLP_INT_NON_SECURE (The NVIC_BLE_SLP_INT_NON_SECURE interrupt is active)
  [4] BLE_CRYPT — Set the BLE_CRYPT interrupt as non-secure
    1=NVIC_BLE_CRYPT_INT_NON_SECURE (The NVIC_BLE_CRYPT_INT_NON_SECURE interrupt is active)
  [3] BLE_TIMESTAMP_TGT2 — Set the BLE_TIMESTAMP_TGT2 interrupt as non-secure
    1=NVIC_BLE_TIMESTAMP_TGT2_INT_NON_SECURE (The NVIC_BLE_TIMESTAMP_TGT2_INT_NON_SECURE interrupt is active)
  [2] BLE_TIMESTAMP_TGT1 — Set the BLE_TIMESTAMP_TGT1 interrupt as non-secure
    1=NVIC_BLE_TIMESTAMP_TGT1_INT_NON_SECURE (The NVIC_BLE_TIMESTAMP_TGT1_INT_NON_SECURE interrupt is active)
  [1] BLE_FINETGT — Set the BLE_FINETGT interrupt as non-secure
    1=NVIC_BLE_FINETGT_INT_NON_SECURE (The NVIC_BLE_FINETGT_INT_NON_SECURE interrupt is active)
  [0] BLE_SW — Set the BLE_SW interrupt as non-secure
    1=NVIC_BLE_SW_INT_NON_SECURE (The NVIC_BLE_SW_INT_NON_SECURE interrupt is active)
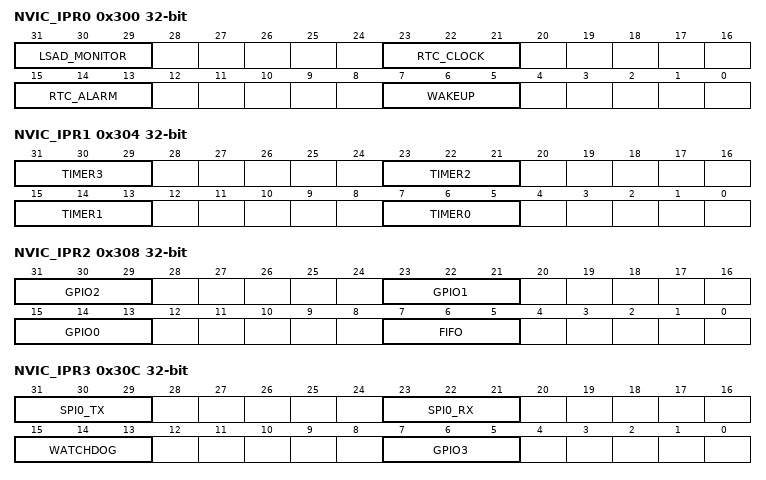
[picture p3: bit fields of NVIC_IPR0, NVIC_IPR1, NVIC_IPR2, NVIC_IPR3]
0x300 NVIC_IPR0 — NVIC External Interrupt Priority Register 0
  [31:29] LSAD_MONITOR — Configure the LSAD_MONITOR interrupt priority
  [23:21] RTC_CLOCK — Configure the RTC_CLOCK interrupt priority
  [15:13] RTC_ALARM — Configure the RTC_ALARM interrupt priority
  [7:5] WAKEUP — Configure the WAKEUP interrupt priority
0x304 NVIC_IPR1 — NVIC External Interrupt Priority Register 1
  [8n+7:8n+5] TIMER{n} (n=0..3) — Configure the TIMER{n} interrupt priority
0x308 NVIC_IPR2 — NVIC External Interrupt Priority Register 2
  [31:29] GPIO2 — Configure the GPIO2 interrupt priority
  [23:21] GPIO1 — Configure the GPIO1 interrupt priority
  [15:13] GPIO0 — Configure the GPIO0 interrupt priority
  [7:5] FIFO — Configure the FIFO interrupt priority
0x30C NVIC_IPR3 — NVIC External Interrupt Priority Register 3
  [31:29] SPI0_TX — Configure the SPI0_TX interrupt priority
  [23:21] SPI0_RX — Configure the SPI0_RX interrupt priority
  [15:13] WATCHDOG — Configure the WATCHDOG interrupt priority
  [7:5] GPIO3 — Configure the GPIO3 interrupt priority
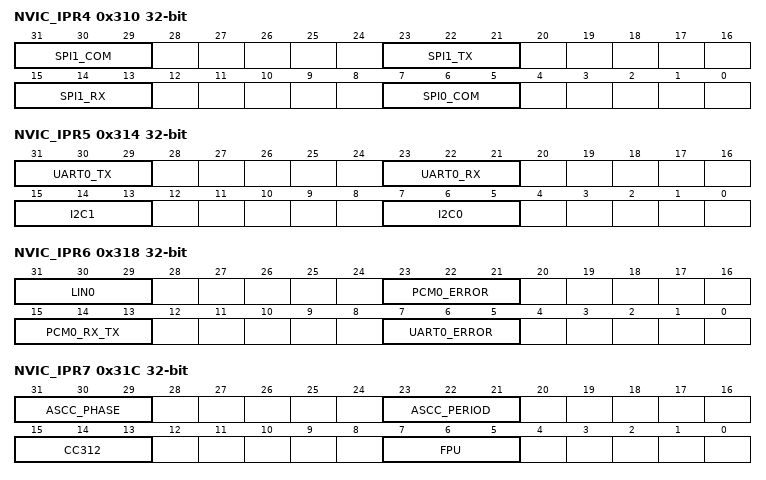
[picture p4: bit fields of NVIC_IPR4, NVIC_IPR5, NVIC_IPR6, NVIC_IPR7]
0x310 NVIC_IPR4 — NVIC External Interrupt Priority Register 4
  [31:29] SPI1_COM — Configure the SPI1_COM interrupt priority
  [23:21] SPI1_TX — Configure the SPI1_TX interrupt priority
  [15:13] SPI1_RX — Configure the SPI1_RX interrupt priority
  [7:5] SPI0_COM — Configure the SPI0_COM interrupt priority
0x314 NVIC_IPR5 — NVIC External Interrupt Priority Register 5
  [31:29] UART0_TX — Configure the UART0_TX interrupt priority
  [23:21] UART0_RX — Configure the UART0_RX interrupt priority
  [15:13] I2C1 — Configure the I2C1 interrupt priority
  [7:5] I2C0 — Configure the I2C0 interrupt priority
0x318 NVIC_IPR6 — NVIC External Interrupt Priority Register 6
  [31:29] LIN0 — Configure the LIN0 interrupt priority
  [23:21] PCM0_ERROR — Configure the PCM0_ERROR interrupt priority
  [15:13] PCM0_RX_TX — Configure the PCM0_RX_TX interrupt priority
  [7:5] UART0_ERROR — Configure the UART0_ERROR interrupt priority
0x31C NVIC_IPR7 — NVIC External Interrupt Priority Register 7
  [31:29] ASCC_PHASE — Configure the ASCC_PHASE interrupt priority
  [23:21] ASCC_PERIOD — Configure the ASCC_PERIOD interrupt priority
  [15:13] CC312 — Configure the CC312 interrupt priority
  [7:5] FPU — Configure the FPU interrupt priority
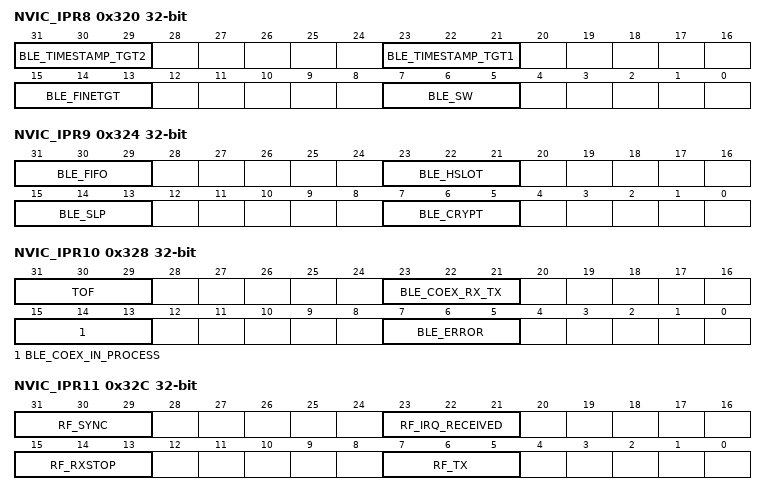
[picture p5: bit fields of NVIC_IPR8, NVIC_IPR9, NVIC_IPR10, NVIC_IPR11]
0x320 NVIC_IPR8 — NVIC External Interrupt Priority Register 8
  [31:29] BLE_TIMESTAMP_TGT2 — Configure the BLE_TIMESTAMP_TGT2 interrupt priority
  [23:21] BLE_TIMESTAMP_TGT1 — Configure the BLE_TIMESTAMP_TGT1 interrupt priority
  [15:13] BLE_FINETGT — Configure the BLE_FINETGT interrupt priority
  [7:5] BLE_SW — Configure the BLE_SW interrupt priority
0x324 NVIC_IPR9 — NVIC External Interrupt Priority Register 9
  [31:29] BLE_FIFO — Configure the BLE_FIFO interrupt priority
  [23:21] BLE_HSLOT — Configure the BLE_HSLOT interrupt priority
  [15:13] BLE_SLP — Configure the BLE_SLP interrupt priority
  [7:5] BLE_CRYPT — Configure the BLE_CRYPT interrupt priority
0x328 NVIC_IPR10 — NVIC External Interrupt Priority Register 10
  [31:29] TOF — Configure the TOF interrupt priority
  [23:21] BLE_COEX_RX_TX — Configure the BLE_COEX_RX_TX interrupt priority
  [15:13] BLE_COEX_IN_PROCESS — Configure the BLE_COEX_IN_PROCESS interrupt priority
  [7:5] BLE_ERROR — Configure the BLE_ERROR interrupt priority
0x32C NVIC_IPR11 — NVIC External Interrupt Priority Register 11
  [31:29] RF_SYNC — Configure the RF_SYNC interrupt priority
  [23:21] RF_IRQ_RECEIVED — Configure the RF_IRQ_RECEIVED interrupt priority
  [15:13] RF_RXSTOP — Configure the RF_RXSTOP interrupt priority
  [7:5] RF_TX — Configure the RF_TX interrupt priority
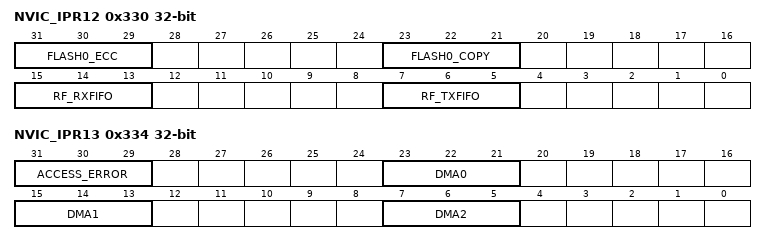
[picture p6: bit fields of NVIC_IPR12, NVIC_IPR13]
0x330 NVIC_IPR12 — NVIC External Interrupt Priority Register 12
  [31:29] FLASH0_ECC — Configure the FLASH0_ECC interrupt priority
  [23:21] FLASH0_COPY — Configure the FLASH0_COPY interrupt priority
  [15:13] RF_RXFIFO — Configure the RF_RXFIFO interrupt priority
  [7:5] RF_TXFIFO — Configure the RF_TXFIFO interrupt priority
0x334 NVIC_IPR13 — NVIC External Interrupt Priority Register 13
  [31:29] ACCESS_ERROR — Configure the ACCESS_ERROR interrupt priority
  [23:21] DMA0 — Configure the DMA0 interrupt priority
  [15:13] DMA1 — Configure the DMA1 interrupt priority
  [7:5] DMA2 — Configure the DMA2 interrupt priority
0x338 NVIC_IPR14 — NVIC External Interrupt Priority Register 14
  [7:5] DMA3 — Configure the DMA3 interrupt priority
0x20000 NVIC_ISER0_NS access not given reset not defined — NVIC External Interrupt Set Enable Register 0
0x20004 NVIC_ISER1_NS access not given reset not defined — NVIC External Interrupt Set Enable Register 1
0x20080 NVIC_ICER0_NS access not given reset not defined — NVIC External Interrupt Clear Enable Register 0
0x20084 NVIC_ICER1_NS access not given reset not defined — NVIC External Interrupt Clear Enable Register 1
0x20100 NVIC_ISPR0_NS access not given reset not defined — NVIC External Interrupt Set Pending Register 0
0x20104 NVIC_ISPR1_NS access not given reset not defined — NVIC External Interrupt Set Pending Register 1
0x20180 NVIC_ICPR0_NS access not given reset not defined — NVIC External Interrupt Clear Pending Register 0
0x20184 NVIC_ICPR1_NS access not given reset not defined — NVIC External Interrupt Clear Pending Register 1
0x20200 NVIC_IABR0_NS access not given reset not defined — NVIC External Interrupt Active Register 0
0x20204 NVIC_IABR1_NS access not given reset not defined — NVIC External Interrupt Active Register 1
{0x20300+4i} NVIC_IPR{i}_NS access not given reset not defined (i=0..13) — NVIC External Interrupt Priority Register {i}
0x20438 NVIC_IPR14_NS access not given reset not defined — NVIC External Interrupt Priority Register 14
